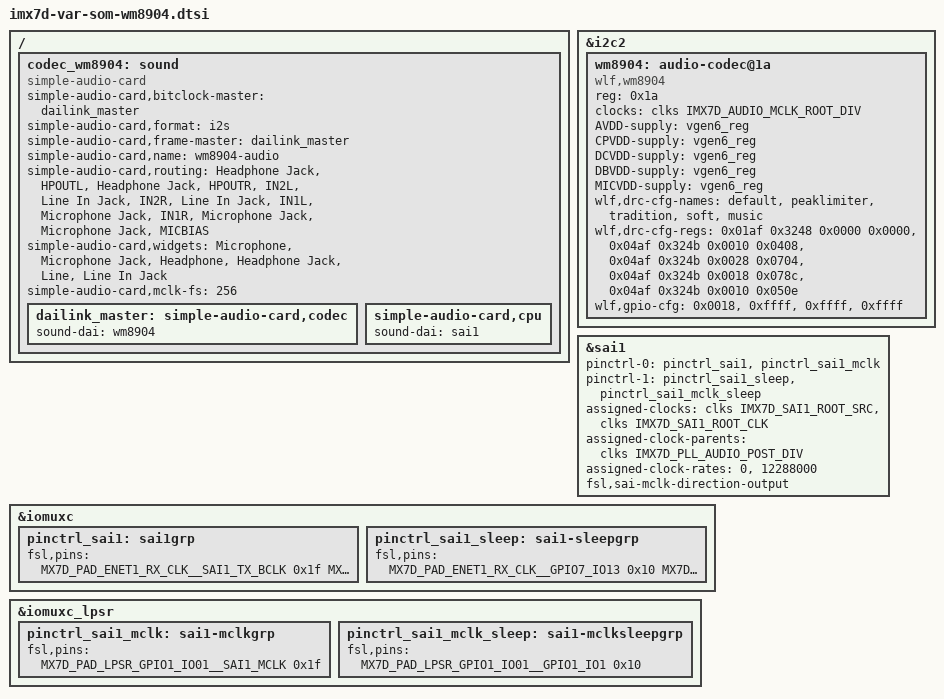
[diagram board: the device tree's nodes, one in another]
// SPDX-License-Identifier: (GPL-2.0+ OR MIT)
/*
 * Common dtsi for WM8904 support on Variscite VAR-SOM-MX7
 *
 * Link: https://variscite.com/system-on-module-som/i-mx-7/var-som-mx7/
 *
 * Copyright (C) 2026 Variscite Ltd. - https://www.variscite.com/
 *
 */

/ {
	codec_wm8904: sound {
		compatible = "simple-audio-card";
		simple-audio-card,bitclock-master = <&dailink_master>;
		simple-audio-card,format = "i2s";
		simple-audio-card,frame-master = <&dailink_master>;
		simple-audio-card,name = "wm8904-audio";
		simple-audio-card,routing =
			"Headphone Jack", "HPOUTL",
			"Headphone Jack", "HPOUTR",
			"IN2L", "Line In Jack",
			"IN2R", "Line In Jack",
			"IN1L", "Microphone Jack",
			"IN1R", "Microphone Jack",
			"Microphone Jack", "MICBIAS";
		simple-audio-card,widgets =
			"Microphone", "Microphone Jack",
			"Headphone", "Headphone Jack",
			"Line", "Line In Jack";
		simple-audio-card,mclk-fs = <256>;

		dailink_master: simple-audio-card,codec {
			sound-dai = <&wm8904>;
		};

		simple-audio-card,cpu {
			sound-dai = <&sai1>;
		};
	};
};

&i2c2 {
	wm8904: audio-codec@1a {
		compatible = "wlf,wm8904";
		reg = <0x1a>;
		#sound-dai-cells = <0>;
		clocks = <&clks IMX7D_AUDIO_MCLK_ROOT_DIV>;
		clock-names = "mclk";
		AVDD-supply = <&vgen6_reg>;
		CPVDD-supply = <&vgen6_reg>;
		DCVDD-supply = <&vgen6_reg>;
		DBVDD-supply = <&vgen6_reg>;
		MICVDD-supply = <&vgen6_reg>;
		wlf,drc-cfg-names = "default", "peaklimiter", "tradition",
				    "soft", "music";
		/*
		 * Config registers per name, respectively:
		 * KNEE_IP = 0,   KNEE_OP = 0,     HI_COMP = 1,   LO_COMP = 1
		 * KNEE_IP = -24, KNEE_OP = -6,    HI_COMP = 1/4, LO_COMP = 1
		 * KNEE_IP = -42, KNEE_OP = -3,    HI_COMP = 0,   LO_COMP = 1
		 * KNEE_IP = -45, KNEE_OP = -9,    HI_COMP = 1/8, LO_COMP = 1
		 * KNEE_IP = -30, KNEE_OP = -10.5, HI_COMP = 1/4, LO_COMP = 1
		 */
		wlf,drc-cfg-regs = /bits/ 16 <0x01af 0x3248 0x0000 0x0000>,
				   /bits/ 16 <0x04af 0x324b 0x0010 0x0408>,
				   /bits/ 16 <0x04af 0x324b 0x0028 0x0704>,
				   /bits/ 16 <0x04af 0x324b 0x0018 0x078c>,
				   /bits/ 16 <0x04af 0x324b 0x0010 0x050e>;
		/* GPIO1 = DMIC_CLK, don't touch others */
		wlf,gpio-cfg = <0x0018>, <0xffff>, <0xffff>, <0xffff>;
	};
};

&sai1 {
	pinctrl-names = "default", "sleep";
	pinctrl-0 = <&pinctrl_sai1>, <&pinctrl_sai1_mclk>;
	pinctrl-1 = <&pinctrl_sai1_sleep>, <&pinctrl_sai1_mclk_sleep>;
	assigned-clocks = <&clks IMX7D_SAI1_ROOT_SRC>,
			  <&clks IMX7D_SAI1_ROOT_CLK>;
	assigned-clock-parents = <&clks IMX7D_PLL_AUDIO_POST_DIV>;
	assigned-clock-rates = <0>, <12288000>;
	fsl,sai-mclk-direction-output;
	status = "okay";
};

&iomuxc {
	pinctrl_sai1: sai1grp {
		fsl,pins = <
			MX7D_PAD_ENET1_RX_CLK__SAI1_TX_BCLK		0x1f
			MX7D_PAD_ENET1_CRS__SAI1_TX_SYNC		0x1f
			MX7D_PAD_ENET1_COL__SAI1_TX_DATA0		0x30
			MX7D_PAD_ENET1_TX_CLK__SAI1_RX_DATA0		0x1f
		>;
	};

	pinctrl_sai1_sleep: sai1-sleepgrp {
		fsl,pins = <
			MX7D_PAD_ENET1_RX_CLK__GPIO7_IO13		0x10
			MX7D_PAD_ENET1_CRS__GPIO7_IO14			0x10
			MX7D_PAD_ENET1_COL__GPIO7_IO15			0x10
			MX7D_PAD_ENET1_TX_CLK__GPIO7_IO12		0x10
		>;
	};
};

&iomuxc_lpsr {
	pinctrl_sai1_mclk: sai1-mclkgrp {
		fsl,pins = <
			MX7D_PAD_LPSR_GPIO1_IO01__SAI1_MCLK		0x1f
		>;
	};

	pinctrl_sai1_mclk_sleep: sai1-mclksleepgrp {
		fsl,pins = <
			MX7D_PAD_LPSR_GPIO1_IO01__GPIO1_IO1		0x10
		>;
	};
};
